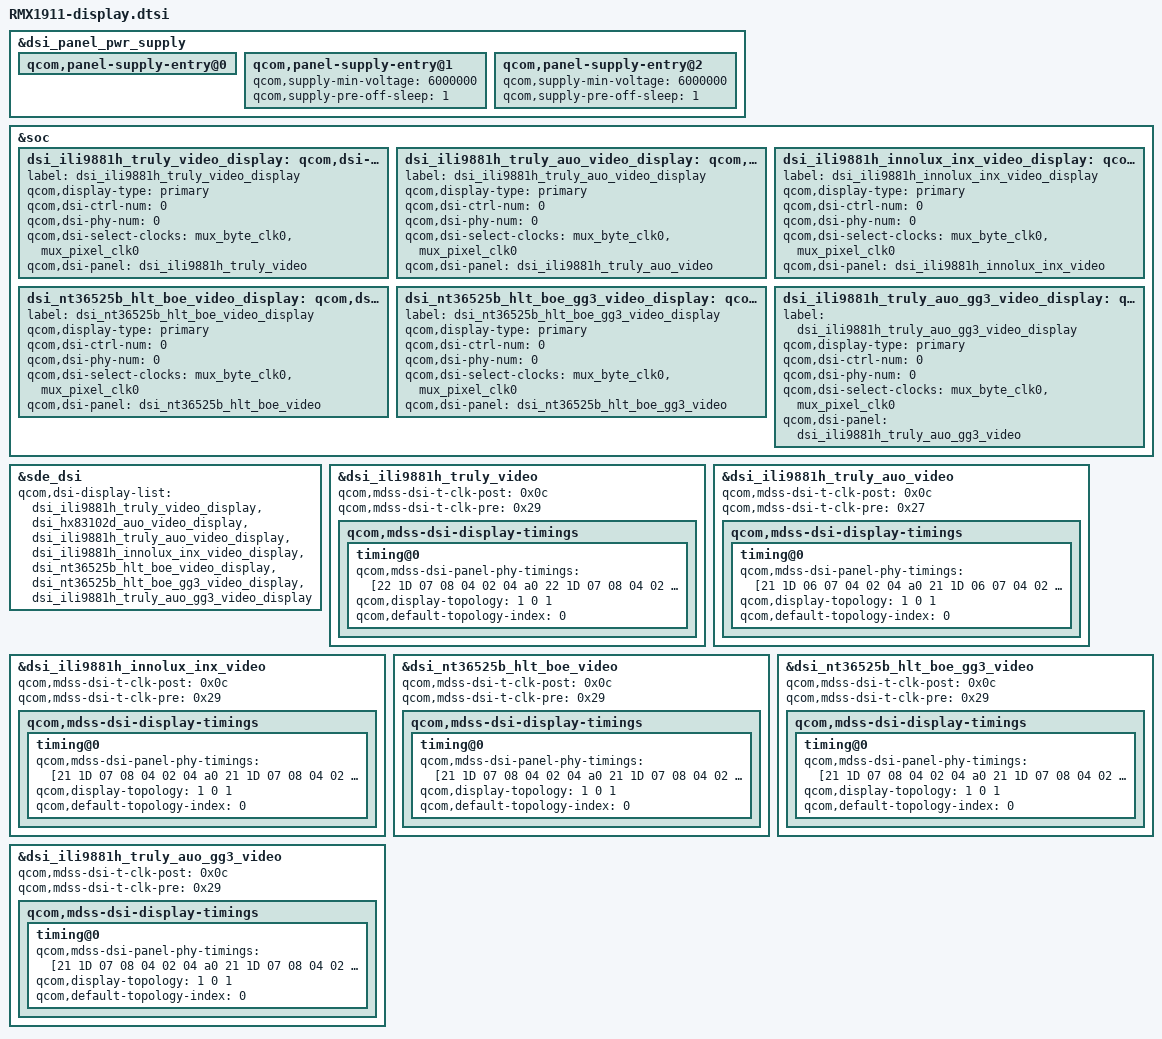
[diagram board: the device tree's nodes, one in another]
/* Copyright (c) 2019-2020, The Linux Foundation. All rights reserved.
 *
 * This program is free software; you can redistribute it and/or modify
 * it under the terms of the GNU General Public License version 2 and
 * only version 2 as published by the Free Software Foundation.
 *
 * This program is distributed in the hope that it will be useful,
 * but WITHOUT ANY WARRANTY; without even the implied warranty of
 * MERCHANTABILITY or FITNESS FOR A PARTICULAR PURPOSE.  See the
 * GNU General Public License for more details.
 */

#include "display/dsi-panel-ili9881h-truly-singlemipi-hdp-video.dtsi"
#include "display/dsi-panel-ili9881h-truly-auo-singlemipi-hdp-video.dtsi"
#include "display/dsi-panel-ili9881h-innolux-inx-singlemipi-hdp-video.dtsi"
#include "display/dsi-panel-nt36525b-hlt-boe-singlemipi-hdp-video.dtsi"
#include "display/dsi-panel-ili9881h-truly-auo-singlemipi-hdp-gg3-video.dtsi"
#include "display/dsi-panel-nt36525b-hlt-boe-singlemipi-hdp-gg3-video.dtsi"

&dsi_panel_pwr_supply {
	qcom,panel-supply-entry@0 {
		/delete-property/ qcom,supply-post-on-sleep;
	};

	qcom,panel-supply-entry@1 {
		qcom,supply-min-voltage = <6000000>;
		qcom,supply-pre-off-sleep = <1>;
	};

	qcom,panel-supply-entry@2 {
		qcom,supply-min-voltage = <6000000>;
                /delete-property/ qcom,supply-post-on-sleep;
		qcom,supply-pre-off-sleep = <1>;
        };
};

&soc {
        dsi_ili9881h_truly_video_display: qcom,dsi-display@5 {
		label = "dsi_ili9881h_truly_video_display";
		qcom,display-type = "primary";

		qcom,dsi-ctrl-num = <0>;
		qcom,dsi-phy-num = <0>;
		qcom,dsi-select-clocks = "mux_byte_clk0", "mux_pixel_clk0";

		qcom,dsi-panel = <&dsi_ili9881h_truly_video>;
	};

	dsi_ili9881h_truly_auo_video_display: qcom,dsi-display@6 {
		label = "dsi_ili9881h_truly_auo_video_display";
		qcom,display-type = "primary";

		qcom,dsi-ctrl-num = <0>;
		qcom,dsi-phy-num = <0>;
		qcom,dsi-select-clocks = "mux_byte_clk0", "mux_pixel_clk0";

		qcom,dsi-panel = <&dsi_ili9881h_truly_auo_video>;
	};

	dsi_ili9881h_innolux_inx_video_display: qcom,dsi-display@13 {
		label = "dsi_ili9881h_innolux_inx_video_display";
		qcom,display-type = "primary";

		qcom,dsi-ctrl-num = <0>;
		qcom,dsi-phy-num = <0>;
		qcom,dsi-select-clocks = "mux_byte_clk0", "mux_pixel_clk0";

		qcom,dsi-panel = <&dsi_ili9881h_innolux_inx_video>;
	};

	dsi_nt36525b_hlt_boe_video_display: qcom,dsi-display@14 {
		label = "dsi_nt36525b_hlt_boe_video_display";
		qcom,display-type = "primary";

		qcom,dsi-ctrl-num = <0>;
		qcom,dsi-phy-num = <0>;
		qcom,dsi-select-clocks = "mux_byte_clk0", "mux_pixel_clk0";

		qcom,dsi-panel = <&dsi_nt36525b_hlt_boe_video>;
	};

	dsi_nt36525b_hlt_boe_gg3_video_display: qcom,dsi-display@15 {
		label = "dsi_nt36525b_hlt_boe_gg3_video_display";
		qcom,display-type = "primary";

		qcom,dsi-ctrl-num = <0>;
		qcom,dsi-phy-num = <0>;
		qcom,dsi-select-clocks = "mux_byte_clk0", "mux_pixel_clk0";

		qcom,dsi-panel = <&dsi_nt36525b_hlt_boe_gg3_video>;
	};

	dsi_ili9881h_truly_auo_gg3_video_display: qcom,dsi-display@16 {
		label = "dsi_ili9881h_truly_auo_gg3_video_display";
		qcom,display-type = "primary";

		qcom,dsi-ctrl-num = <0>;
		qcom,dsi-phy-num = <0>;
		qcom,dsi-select-clocks = "mux_byte_clk0", "mux_pixel_clk0";

		qcom,dsi-panel = <&dsi_ili9881h_truly_auo_gg3_video>;
	};
};

&sde_dsi {
	qcom,dsi-display-list = <&dsi_ili9881h_truly_video_display
				&dsi_hx83102d_auo_video_display
				&dsi_ili9881h_truly_auo_video_display
				&dsi_ili9881h_innolux_inx_video_display
				&dsi_nt36525b_hlt_boe_video_display
				&dsi_nt36525b_hlt_boe_gg3_video_display
				&dsi_ili9881h_truly_auo_gg3_video_display>;

};

&dsi_ili9881h_truly_video {
	qcom,mdss-dsi-t-clk-post = <0x0c>;
	qcom,mdss-dsi-t-clk-pre = <0x29>;
	qcom,mdss-dsi-display-timings {
		timing@0{
			qcom,mdss-dsi-panel-phy-timings =
				[22 1D 07 08 04 02 04 a0
				22 1D 07 08 04 02 04 a0
				22 1D 07 08 04 02 04 a0
				22 1D 07 08 04 02 04 a0
				22 16 06 07 04 02 04 a0];

			qcom,display-topology = <1 0 1>;
			qcom,default-topology-index = <0>;
		};
	};
};

&dsi_ili9881h_truly_auo_video {
	qcom,mdss-dsi-t-clk-post = <0x0c>;
	qcom,mdss-dsi-t-clk-pre = <0x27>;
	qcom,mdss-dsi-display-timings {
		timing@0{
			qcom,mdss-dsi-panel-phy-timings =
				[21 1D 06 07 04 02 04 a0
				21 1D 06 07 04 02 04 a0
				21 1D 06 07 04 02 04 a0
				21 1D 06 07 04 02 04 a0
				21 14 06 07 04 02 04 a0];

			qcom,display-topology = <1 0 1>;
			qcom,default-topology-index = <0>;
		};
	};
};

&dsi_ili9881h_innolux_inx_video {
	qcom,mdss-dsi-t-clk-post = <0x0c>;
	qcom,mdss-dsi-t-clk-pre = <0x29>;
	qcom,mdss-dsi-display-timings {
		timing@0{
			qcom,mdss-dsi-panel-phy-timings =
				[21 1D 07 08 04 02 04 a0
				21 1D 07 08 04 02 04 a0
				21 1D 07 08 04 02 04 a0
				21 1D 07 08 04 02 04 a0
				21 16 06 07 04 02 04 a0];

			qcom,display-topology = <1 0 1>;
			qcom,default-topology-index = <0>;
		};
	};
};

&dsi_nt36525b_hlt_boe_video {
	qcom,mdss-dsi-t-clk-post = <0x0c>;
	qcom,mdss-dsi-t-clk-pre = <0x29>;
	qcom,mdss-dsi-display-timings {
		timing@0{
			qcom,mdss-dsi-panel-phy-timings =
				[21 1D 07 08 04 02 04 a0
				21 1D 07 08 04 02 04 a0
				21 1D 07 08 04 02 04 a0
				21 1D 07 08 04 02 04 a0
				21 16 06 07 04 02 04 a0];

			qcom,display-topology = <1 0 1>;
			qcom,default-topology-index = <0>;
		};
	};
};

&dsi_nt36525b_hlt_boe_gg3_video {
	qcom,mdss-dsi-t-clk-post = <0x0c>;
	qcom,mdss-dsi-t-clk-pre = <0x29>;
	qcom,mdss-dsi-display-timings {
		timing@0{
			qcom,mdss-dsi-panel-phy-timings =
				[21 1D 07 08 04 02 04 a0
				21 1D 07 08 04 02 04 a0
				21 1D 07 08 04 02 04 a0
				21 1D 07 08 04 02 04 a0
				21 16 06 07 04 02 04 a0];

			qcom,display-topology = <1 0 1>;
			qcom,default-topology-index = <0>;
		};
	};
};

&dsi_ili9881h_truly_auo_gg3_video {
	qcom,mdss-dsi-t-clk-post = <0x0c>;
	qcom,mdss-dsi-t-clk-pre = <0x29>;
	qcom,mdss-dsi-display-timings {
		timing@0{
			qcom,mdss-dsi-panel-phy-timings =
				[21 1D 07 08 04 02 04 a0
				21 1D 07 08 04 02 04 a0
				21 1D 07 08 04 02 04 a0
				21 1D 07 08 04 02 04 a0
				21 16 06 07 04 02 04 a0];

			qcom,display-topology = <1 0 1>;
			qcom,default-topology-index = <0>;
		};
	};
};
